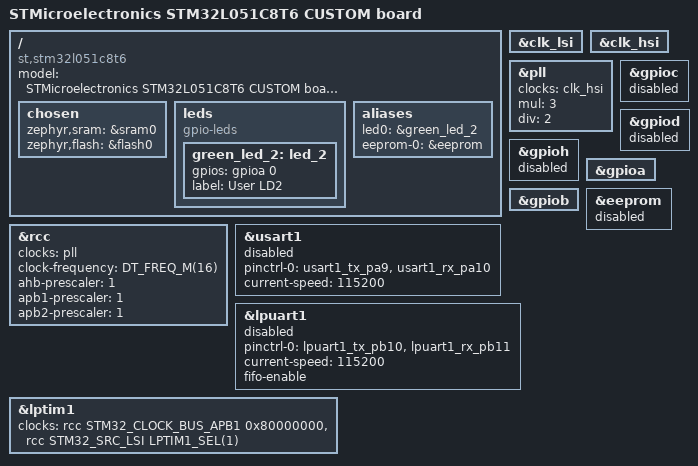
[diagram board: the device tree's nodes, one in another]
/*
* Copyright (c) 2026 Elius Faustine <elius@vortan.io>
*
* SPDX-License-Identifier: Apache-2.0
*/

/dts-v1/;
#include <st/l0/stm32l051X8.dtsi>
#include <st/l0/stm32l051c(6-8)tx-pinctrl.dtsi>
#include <zephyr/dt-bindings/input/input-event-codes.h>

/ {
	model = "STMicroelectronics STM32L051C8T6 CUSTOM board";
	compatible = "st,stm32l051c8t6";
	
	chosen {
		zephyr,sram = &sram0;
		zephyr,flash = &flash0;
	};
	
	leds: leds {
		compatible = "gpio-leds";
		green_led_2: led_2 {
			gpios = <&gpioa 0 GPIO_ACTIVE_HIGH>;
			label = "User LD2";
		};
	};
	
	aliases {
		led0 = &green_led_2;
		eeprom-0 = &eeprom;
	};
};

&clk_lsi {
	status = "okay";
};

&clk_hsi {
	status = "okay";
};

&pll {
	clocks = <&clk_hsi>;
	mul = <3>;
	div = <2>;
	status = "okay";
};

&rcc {
	clocks = <&pll>;
	clock-frequency = <DT_FREQ_M(16)>;
	ahb-prescaler = <1>;
	apb1-prescaler = <1>;
	apb2-prescaler = <1>;
};

/* Due to limited available memory, don't enable gpioc gpiod and gpiof */
/* (Test cases fail due to 'SRAM' region overflow) */
&gpioc {
	status = "disabled";
};

&gpiod {
	status = "disabled";
};

&gpioh {
	status = "disabled";
};

&gpioa {
	status = "okay";
};

&gpiob {
	status = "okay";
};

&usart1 {
	pinctrl-0 = <&usart1_tx_pa9 &usart1_rx_pa10>;
	pinctrl-names = "default";
	current-speed = <115200>;
	status = "disabled";
};

&lpuart1 {
	pinctrl-0 = <&lpuart1_tx_pb10 &lpuart1_rx_pb11>;
	pinctrl-names = "default";
	current-speed = <115200>;
	fifo-enable;
	status = "disabled";
};

&lptim1 {
	status = "okay";
};

stm32_lp_tick_source: &lptim1 {
	clocks = <&rcc STM32_CLOCK_BUS_APB1 0x80000000>,
	<&rcc STM32_SRC_LSI LPTIM1_SEL(1)>;
	status = "okay";
};

&eeprom {
	status = "disabled";
};
